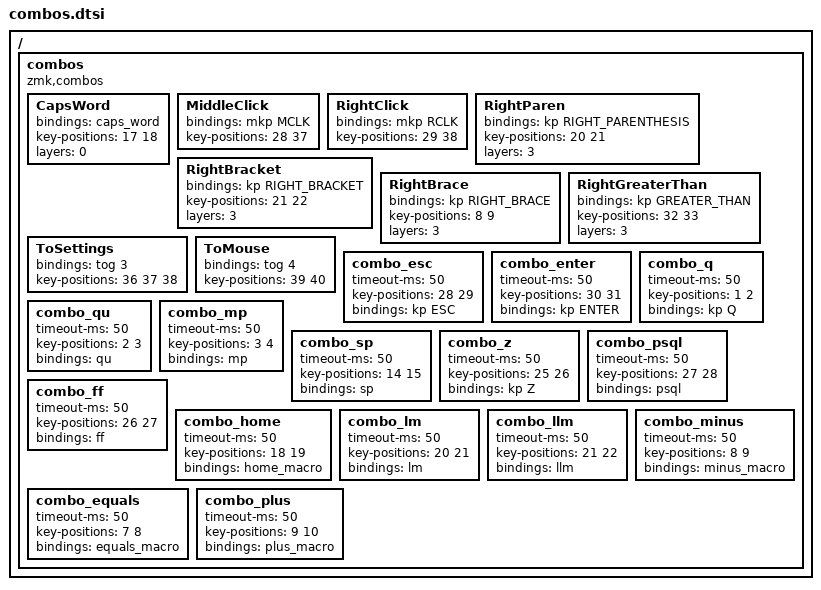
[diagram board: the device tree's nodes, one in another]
/ {
    combos {
        compatible = "zmk,combos";

        CapsWord {
            bindings = <&caps_word>;
            key-positions = <17 18>;
            layers = <0>;
        };

        MiddleClick {
            bindings = <&mkp MCLK>;
            key-positions = <28 37>;
        };

        RightClick {
            bindings = <&mkp RCLK>;
            key-positions = <29 38>;
        };

        RightParen {
            bindings = <&kp RIGHT_PARENTHESIS>;
            key-positions = <20 21>;
            layers = <3>;
        };

        RightBracket {
            bindings = <&kp RIGHT_BRACKET>;
            key-positions = <21 22>;
            layers = <3>;
        };

        RightBrace {
            bindings = <&kp RIGHT_BRACE>;
            key-positions = <8 9>;
            layers = <3>;
        };

        RightGreaterThan {
            bindings = <&kp GREATER_THAN>;
            key-positions = <32 33>;
            layers = <3>;
        };

        ToSettings {
            bindings = <&tog 3>;
            key-positions = <36 37 38>;
        };

        ToMouse {
            bindings = <&tog 4>;
            key-positions = <39 40>;
        };

        combo_esc {
            timeout-ms = <50>;
            key-positions = <28 29>;
            bindings = <&kp ESC>;
        };

        combo_enter {
            timeout-ms = <50>;
            key-positions = <30 31>;
            bindings = <&kp ENTER>;
        };

        combo_q {
            timeout-ms = <50>;
            key-positions = <1 2>;
            bindings = <&kp Q>;
        };

        combo_qu {
            timeout-ms = <50>;
            key-positions = <2 3>;
            bindings = <&qu>;
        };
        combo_mp {
            timeout-ms = <50>;
            key-positions = <3 4>;
            bindings = <&mp>;
        };
        combo_sp {
            timeout-ms = <50>;
            key-positions = <14 15>;
            bindings = <&sp>;
        };

        combo_z {
            timeout-ms = <50>;
            key-positions = <25 26>;
            bindings = <&kp Z>;
        };

        combo_psql {
            timeout-ms = <50>;
            key-positions = <27 28>;
            bindings = <&psql>;
        };

        combo_ff {
            timeout-ms = <50>;
            key-positions = <26 27>;
            bindings = <&ff>;
        };
        combo_home {
            timeout-ms = <50>;
            key-positions = <18 19>;
            bindings = <&home_macro>;
        };
        combo_lm {
            timeout-ms = <50>;
            key-positions = <20 21>;
            bindings = <&lm>;
        };
        combo_llm {
            timeout-ms = <50>;
            key-positions = <21 22>;
            bindings = <&llm>;
        };
        combo_minus {
            timeout-ms = <50>;
            key-positions = <8 9>;
            bindings = <&minus_macro>;
        };
        combo_equals {
            timeout-ms = <50>;
            key-positions = <7 8>;
            bindings = <&equals_macro>;
        };
        combo_plus {
            timeout-ms = <50>;
            key-positions = <9 10>;
            bindings = <&plus_macro>;
        };
    };
};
